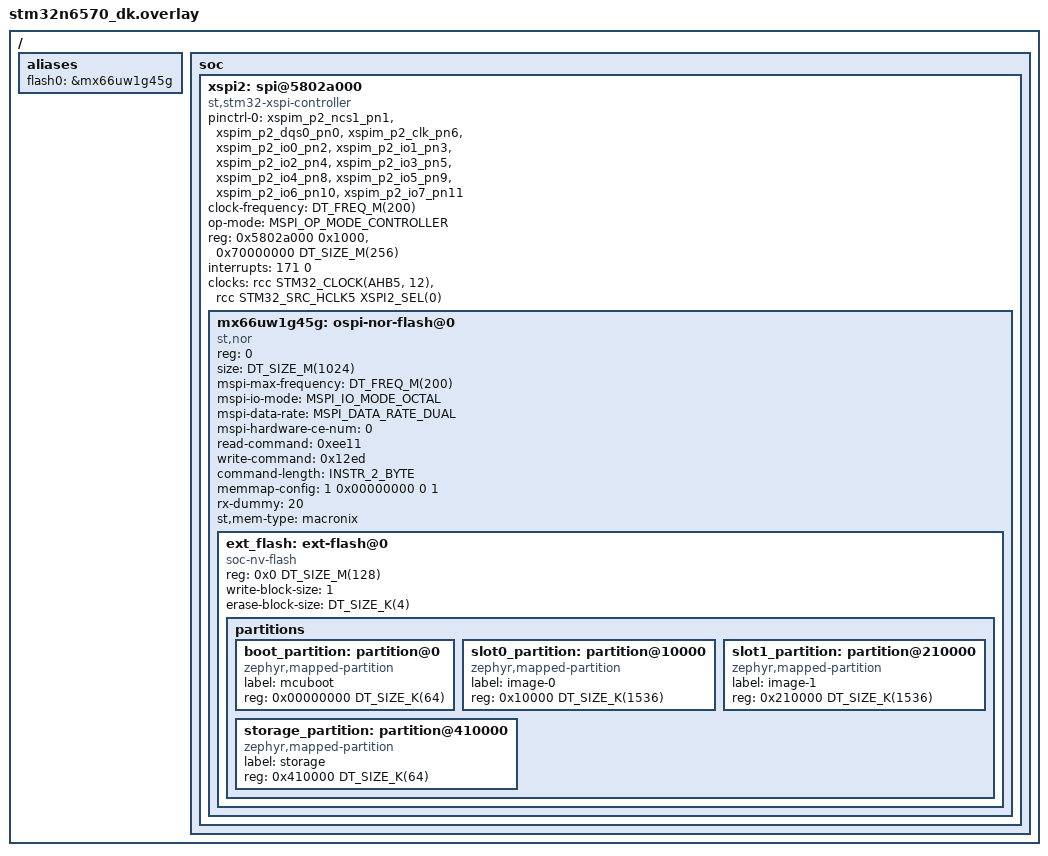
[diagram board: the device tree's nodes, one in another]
/*
 * Copyright (c) 2026 EXALT Technologies
 *
 * SPDX-License-Identifier: Apache-2.0
 */

/delete-node/ &xspi2;

/ {
	aliases {
		/* The sample gets the DT_ALIAS(flash0) as the mspi device */
		flash0 = &mx66uw1g45g;
	};

	soc {
		xspi2: spi@5802a000 {
			compatible = "st,stm32-xspi-controller";
			pinctrl-0 = <&xspim_p2_ncs1_pn1 &xspim_p2_dqs0_pn0 &xspim_p2_clk_pn6
				     &xspim_p2_io0_pn2 &xspim_p2_io1_pn3 &xspim_p2_io2_pn4
				     &xspim_p2_io3_pn5 &xspim_p2_io4_pn8 &xspim_p2_io5_pn9
				     &xspim_p2_io6_pn10 &xspim_p2_io7_pn11>;
			pinctrl-names = "default";
			clock-frequency = <DT_FREQ_M(200)>;
			#address-cells = <1>;
			#size-cells = <0>;
			op-mode = "MSPI_OP_MODE_CONTROLLER";
			reg = <0x5802a000 0x1000>, <0x70000000 DT_SIZE_M(256)>;
			interrupts = <171 0>;
			clock-names = "xspix", "xspi-ker";
			clocks = <&rcc STM32_CLOCK(AHB5, 12)>,
				 <&rcc STM32_SRC_HCLK5 XSPI2_SEL(0)>;
			status = "okay";

			mx66uw1g45g: ospi-nor-flash@0 {
				compatible = "st,nor", "jedec,nor", "mxicy,mx25u";
				reg = <0>;
				size = <DT_SIZE_M(1024)>;
				mspi-max-frequency = <DT_FREQ_M(200)>;
				mspi-io-mode = "MSPI_IO_MODE_OCTAL";
				mspi-data-rate = "MSPI_DATA_RATE_DUAL";
				mspi-hardware-ce-num = <0>;
				read-command = <0xee11>;
				write-command = <0x12ed>;
				command-length = "INSTR_2_BYTE";
				memmap-config = <1 0x00000000 0 1>;
				rx-dummy = <20>;
				st,mem-type = "macronix";
				#address-cells = <1>;
				#size-cells = <1>;
				status = "okay";

				ext_flash: ext-flash@0 {
					compatible = "soc-nv-flash";
					reg = <0x0 DT_SIZE_M(128)>;
					write-block-size = <1>;
					erase-block-size = <DT_SIZE_K(4)>;
					#address-cells = <1>;
					#size-cells = <1>;
					ranges;

					partitions {
						ranges;
						#address-cells = <1>;
						#size-cells = <1>;

						boot_partition: partition@0 {
							compatible = "zephyr,mapped-partition";
							label = "mcuboot";
							reg = <0x00000000 DT_SIZE_K(64)>;
						};

						slot0_partition: partition@10000 {
							compatible = "zephyr,mapped-partition";
							label = "image-0";
							reg = <0x10000 DT_SIZE_K(1536)>;
						};

						slot1_partition: partition@210000 {
							compatible = "zephyr,mapped-partition";
							label = "image-1";
							reg = <0x210000 DT_SIZE_K(1536)>;
						};

						storage_partition: partition@410000 {
							compatible = "zephyr,mapped-partition";
							label = "storage";
							reg = <0x410000 DT_SIZE_K(64)>;
						};
					};
				};
			};
		};
	};
};
